# TM4C129ENCPDT register map
File version: 1.0
CPU: CORTEX_M4 1.0, other endian, MPU, FPU, 3 interrupt priority bits
Registers are 32-bit, read-write, reset 0x0 unless marked. A register's access mark holds for its fields unless they carry their own. Offsets are from the block's base; lines under a group give offsets from that group; [hi:lo] are bit positions; {n}, {i} and the like mark numbered series; 'fields as' and 'values as' point back to an identical list; <NAME> marks a mode.

## Memory map
0x40000000 WATCHDOG0 size 0x1000 — Watchdog Timer register offsets
0x40001000 WATCHDOG1 size 0x1000 — Watchdog Timer register offsets
0x40008000 SSI0 size 0x1000 — SSI register offsets
0x40009000 SSI1 size 0x1000 — SSI register offsets
0x4000A000 SSI2 size 0x1000 — SSI register offsets
0x4000B000 SSI3 size 0x1000 — SSI register offsets
{0x4000C000+0x1000*n} UART{n} size 0x1000 (n=0..7) — UART register offsets
0x40020000 I2C0 size 0x1000 — I2C register offsets
0x40021000 I2C1 size 0x1000 — I2C register offsets
0x40022000 I2C2 size 0x1000 — I2C register offsets
0x40023000 I2C3 size 0x1000 — I2C register offsets
0x40028000 PWM0 size 0x1000 — PWM register offsets
0x4002C000 QEI0 size 0x1000 — QEI register offsets
0x40030000 TIMER0 size 0x1000 — Timer register offsets
0x40031000 TIMER1 size 0x1000 — Timer register offsets
0x40032000 TIMER2 size 0x1000 — Timer register offsets
0x40033000 TIMER3 size 0x1000 — Timer register offsets
0x40034000 TIMER4 size 0x1000 — Timer register offsets
0x40035000 TIMER5 size 0x1000 — Timer register offsets
0x40038000 ADC0 size 0x1000 — ADC register offsets
0x40039000 ADC1 size 0x1000 — ADC register offsets
0x4003C000 COMP size 0x1000 — Comparator register offsets
0x40040000 CAN0 size 0x1000 — CAN register offsets
0x40041000 CAN1 size 0x1000 — CAN register offsets
0x40050000 USB0 size 0x1000 — Univeral Serial Bus register offsets
0x40058000 GPIO_PORTA_AHB size 0x1000 — GPIO register offsets
0x40059000 GPIO_PORTB_AHB size 0x1000 — GPIO register offsets
0x4005A000 GPIO_PORTC_AHB size 0x1000 — GPIO register offsets
0x4005B000 GPIO_PORTD_AHB size 0x1000 — GPIO register offsets
0x4005C000 GPIO_PORTE_AHB size 0x1000 — GPIO register offsets
0x4005D000 GPIO_PORTF_AHB size 0x1000 — GPIO register offsets
0x4005E000 GPIO_PORTG_AHB size 0x1000 — GPIO register offsets
0x4005F000 GPIO_PORTH_AHB size 0x1000 — GPIO register offsets
0x40060000 GPIO_PORTJ_AHB size 0x1000 — GPIO register offsets
0x40061000 GPIO_PORTK size 0x1000 — GPIO register offsets
0x40062000 GPIO_PORTL size 0x1000 — GPIO register offsets
0x40063000 GPIO_PORTM size 0x1000 — GPIO register offsets
0x40064000 GPIO_PORTN size 0x1000 — GPIO register offsets
0x40065000 GPIO_PORTP size 0x1000 — GPIO register offsets
0x40066000 GPIO_PORTQ size 0x1000 — GPIO register offsets
0x400AF000 EEPROM size 0x1000 — EEPROM register offsets
0x400B8000 I2C8 size 0x1000 — I2C register offsets
0x400B9000 I2C9 size 0x1000 — I2C register offsets
0x400C0000 I2C4 size 0x1000 — I2C register offsets
0x400C1000 I2C5 size 0x1000 — I2C register offsets
0x400C2000 I2C6 size 0x1000 — I2C register offsets
0x400C3000 I2C7 size 0x1000 — I2C register offsets
0x400D0000 EPI0 size 0x1000 — External Peripheral Interface register offsets
0x400E0000 TIMER6 size 0x1000 — Timer register offsets
0x400E1000 TIMER7 size 0x1000 — Timer register offsets
0x400EC000 EMAC0 size 0x1000 — EMAC register offsets
0x400F9000 SYSEXC size 0x1000 — System Exception Module register addresses
0x400FC000 HIB size 0x1000 — Hibernation module register addresses
0x400FD000 FLASH_CTRL size 0x2000 — FLASH register offsets
0x400FE000 SYSCTL size 0x1000 — System Control register addresses
0x400FF000 UDMA size 0x1000 — Micro Direct Memory Access register addresses
0x44030000 CCM0 size 0x1000 — EC register offsets
0x44034000 SHAMD5 size 0x2000 — SHA/MD5 register offsets
0x44036000 AES size 0x2000 — AES register offsets
0x44038000 DES size 0x2000 — DES register offsets
0xE000E000 NVIC size 0x1000 — NVIC register addresses

## WATCHDOG0 — Watchdog Timer register offsets
Base 0x40000000
Same registers: WATCHDOG1 0x40001000
0x00 WDT_LOAD — Watchdog Load
  [31:0] WDT_LOAD — [31:0] Watchdog Load Value
0x04 WDT_VALUE — Watchdog Value
  [31:0] WDT_VALUE — [31:0] Watchdog Value
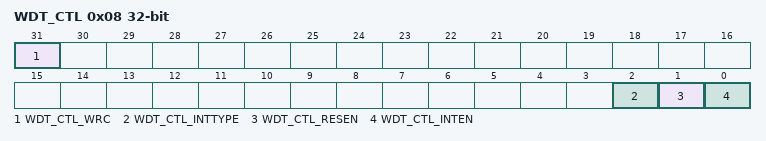
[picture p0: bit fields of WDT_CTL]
0x08 WDT_CTL — Watchdog Control
  [31] WDT_CTL_WRC — [31:31] Write Complete
  [2] WDT_CTL_INTTYPE — [2:2] Watchdog Interrupt Type
  [1] WDT_CTL_RESEN — [1:1] Watchdog Reset Enable
  [0] WDT_CTL_INTEN — [0:0] Watchdog Interrupt Enable
0x0C WDT_ICR — Watchdog Interrupt Clear
  [31:0] WDT_ICR — [31:0] Watchdog Interrupt Clear
0x10 WDT_RIS — Watchdog Raw Interrupt Status
  [0] WDT_RIS_WDTRIS — [0:0] Watchdog Raw Interrupt Status
0x14 WDT_MIS — Watchdog Masked Interrupt Status
  [0] WDT_MIS_WDTMIS — [0:0] Watchdog Masked Interrupt Status
0x418 WDT_TEST — Watchdog Test
  [8] WDT_TEST_STALL — [8:8] Watchdog Stall Enable
0xC00 WDT_LOCK — Watchdog Lock
  [31:0] WDT_LOCK — [31:0] Watchdog Lock
    0=WDT_LOCK_UNLOCKED (Unlocked); 1=WDT_LOCK_LOCKED (Locked); 0x1ACCE551=WDT_LOCK_UNLOCK (Unlocks the watchdog timer)
